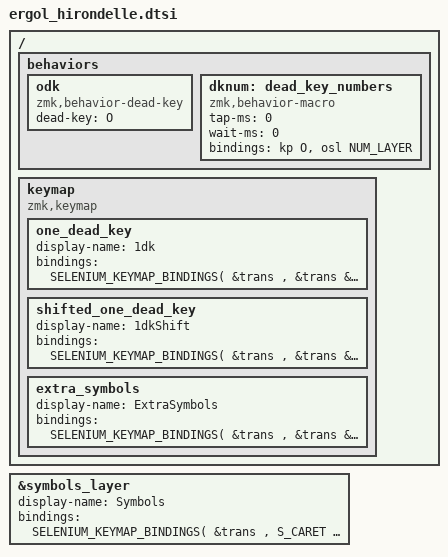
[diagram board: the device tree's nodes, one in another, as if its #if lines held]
// Define a Swallow (hirondelle frenchTM) keymap

// This is a configuration for a keyboard with one key on the outer column, two on fifth 
// and on the internal column (1-23332), called the swallow. It won't work on a raven config
// where you just ignore the keys.

// It is a rework of the hummingbird system written by Nuke.


// ##### How does it work? #####
// To configurate keyboards with median positions, we need to move some of layer keys in
// other positions. This is true for the base layer, the symbol layer... and all the other 
// layers (including the 1DK layer).
// I choose to use the key on the outer columns to place some of the extra letters or actions.

// The configuration in this file replaces the normal base layer by a new base layer with 
// a system to modify the typographic layer.
// It also provides a new typographic layer and a new symbol layer with a system to access 
// a secondary symbol layer.

// This page does not replace the navigation layers or the numeric layers, so you need to deal with that in the
// main keymap as well.


// ####### FAQ #######

// WHY NOT MOVE THE POINT AND KEEP L AND J AS MEDIAN KEYS?
// Nuke au sujet du J et du point : C’est fait parce que sur un Hummingbird, c’est les touches [B](b) et [N](point) qui sautent 
// sur les index en extension basse. Le truc c’est que ça retire le point, et c’est vraiment chiant à rattraper avec la 
// touche typo (vu qu’il y a non seulement pleins de symboles possible à faire, mais en plus il faut l’espace 
// insécable avant le deux-points). Du coup j’esquive ce problème en inversant le j et le point, pour que ça soit 
// le j qui passe en typo. De mon expérience, à l’usage c’est beaucoup plus simple de réapprendre la position du 
// point que de le rattraper après coup.

// OK THEN, WHY NOT KEEPING THE POINT AND THE l IN THE INSIDE COLUMN?
// Nuke: En pratique, tu peux configurer pour virer les touches du haut et tout remonter d’un 
// cran (il me semble que @AstroCephale a fait ça pour l’index gauche sur son hummingbird), mais ça rendrait 
// la heatmap vraiment pas ouf d’avoir le l en haut, donc je recommande pas trop pour la colonne droite


// ####### Let’s do it then #######

// We define a couple of new layers:
#define ODK_LAYER        EXTRA_LAYERS_START_INDEX
#define ODK_SHIFT_LAYER (EXTRA_LAYERS_START_INDEX + 1)
#define EXTRA_SYM_LAYER (EXTRA_LAYERS_START_INDEX + 2)


// Override the symbols layer
//      -- Add access to a sticky layer that can contain the missing symbols on left reach thumb
// (it's not really required for this config (with keys on outer columns) but I kept it in case.
// It does ENTER on tap and access the new layer on hold.
//      -- Get read of the ?, which I can access through the base layer
//      -- Remplace the underscore by le hashtag (I only use the 1D)
//      -- Move the tilde and the pipe in outer columns
&symbols_layer {
  display-name = "Symbols";
  bindings = <SELENIUM_KEYMAP_BINDINGS(
    &trans  , S_CARET S_LT    S_GT    S_DLLR  S_PRCNT  ,  S_AT    S_AMPS  S_STAR  S_SQT   S_GRAVE , &trans ,
    S_TILDE , S_LBRC  S_LPAR  S_RPAR  S_RBRC  S_EQUAL  ,  S_BSLH  S_PLUS  S_MINUS S_FSLH  S_DQT   , S_PIPE ,
    &trans  , &none   S_LBKT  S_RBKT  S_HASH  &none    ,  &none   S_EXCL  S_SEMI  S_COLON &none   , &trans ,
    SYM_NUM_LAYER , &kp SPACE , &sc EXTRA_SYM_LAYER ENTER  ,  &trans , &kp RALT , &trans
  )>;
};

// We need to define a couple of custom behaviours
/ {
  behaviors {
    // Swap out the standard dead key for a one-shot layer to override some of the keys
    TWO_LEVEL_KEY(apos, &EZ_SL(ODK_LAYER), S_EXCL) // ' ! (1dk)
    TWO_LEVEL_KEY(em_dash, &odk V, &odk B) // – — (en-dash, em-dash)

  #ifdef ENABLE_FANCY_DEAD_KEYS
    #define SHIFT_KEY &EZ_SK(LSHIFT)
    odk: odk {
      compatible = "zmk,behavior-dead-key";
      #binding-cells = <1>;
      dead-key = <O>;
    };
  #else
    // Macro to tap Ergo‑L’s ODK before the specified key
    DEAD_KEY(odk, &kp O)
    #define SHIFT_KEY &EZ_SL(ODK_SHIFT_LAYER)
  #endif
    // Same as `odk`, but adds Shift to the specified key
    DEAD_KEY_SHIFT(odks, &kp O)

    dknum: dead_key_numbers {
      compatible = "zmk,behavior-macro";
      #binding-cells = <0>;
      tap-ms = <0>;
      wait-ms = <0>;
      bindings = <&kp O &osl NUM_LAYER>;
    };
  };


  // Extra layers defined specifically for this keymap.
  // They are appended at the end of the base keymap.
  keymap {
    compatible = "zmk,keymap";

    // The turbocharged typo layer. 
    //      -- odk + [letter] means that it gets the normal typo behaviour value for this letter.
    //      -- Add the new letters that do not fit the alpha layer anymore.
    //      -- The Z (Z in ergol too) and B (B in ergol too) move to the left inner column, 
    //         but their associated typo characters (æ et le tiret long) move to the outer columns
    //      -- Since the B replaces the n-tilde (typo on the F-ergo) I move it to replace the 
    //         typo X, the β that can be done with grec layer (1DK + G + letter)
    //      -- The Y (J in ergol) and FSLH (K in ergol) can go to the M-ergo and the H-ergo. 
    //         Since I am not confortable with the M in ergol in general, I’ll move the Y (J in ergol) 
    //         to the H-ergo key and the FSLH (K in ergol)
    //      -- FSLH (K in ergol) goes to the M-ergol. 
    //      -- The typo of U (ergo M), mu, disapears as I can do it in grec (1DK + G + letter)
    //      -- the em_dash is a special behaviour – — (en-dash, em-dash)
    one_dead_key {
      display-name = "1dk";
      bindings = <SELENIUM_KEYMAP_BINDINGS(
        &trans , &trans  &odk W  &odk E  &odk R    &kp Z   ,   &odk N  &kp FSLH  &odk I     &odk O   &trans    , &trans ,
        &odk Z , &odk A  &odk S  &odk D  &odk F    &kp B   ,   &odk H  &odk J    &odk K     &odk L   &odk SEMI , &odk B ,
        &trans , &odk Q  &odk G  &odk C  &em_dash  &trans  ,   &trans  &kp Y     &odk COMMA &odk DOT &odk P    , &trans ,
                        SHIFT_KEY , &dknum , &trans      ,    &trans , &odk SPACE , &trans
      )>;
    };


    // The shifted typo layer
    // It deals with the shifted characters and new letters on the typo layer 
    // Align with the one_dead_key layer!!!
    // Note: this layer is ignored (and useless) if ENABLE_FANCY_DEAD_KEYS is defined
    shifted_one_dead_key {
      display-name = "1dkShift";
      bindings = <SELENIUM_KEYMAP_BINDINGS(
        &trans  , &trans   &odks W  &odks E  &odks R  &kp LS(Z)  ,  &odks N  &kp LS(FSLH) &odks I     &odks O   &trans     , &trans  ,
        &odks Z , &odks A  &odks S  &odks D  &odks F  &kp LS(B)  ,  &odks H  &odks J      &odks K     &odks L   &odks SEMI , &odks B ,
        &trans  , &odks Q  &odks G  &odks C  &odks V  &trans     ,  &trans   &kp LS(Y)    &odks COMMA &odks DOT &odks P    , &trans  ,
                          &trans ,  &odks SPACE , &trans         ,    &trans  , &odks SPACE , &trans
      )>;
    };

    // Extra layer for the symbols that don’t fit on the symbol layer anymore
    //      -- I am keeping it here, and perhaps I should try it at some point, but I moved the symbols to 
    //         the outer colums of the Typography layer to avoid the mental overload of a new layer
    //      -- BT_SEL: bluetooth: Select the 0-indexed bluetooth profile by number
    //      -- &bt_sel1_clr: I assume this key selects the profile 1 on tap, and clear the profile 1 on shift-tap.
    extra_symbols {
      display-name = "ExtraSymbols";
      bindings = <SELENIUM_KEYMAP_BINDINGS(
        &trans , &trans  &trans  &trans  &trans  &bt BT_SEL 2  ,  &bt BT_SEL 0  &trans  &trans  &trans  &trans  , &trans ,
        &trans , S_TILDE &trans  &kp INS S_HASH  &bt_sel1_clr  ,  &trans        S_PIPE  &trans  &trans  S_QMARK , &trans ,
        &trans , &trans  &trans  &trans  &trans  &trans        ,  &trans        &trans  &trans  &trans  &trans  , &trans ,
                               &trans , &trans,  &trans        ,  &trans ,      &trans , &trans
      )>;
    };
  };
};
